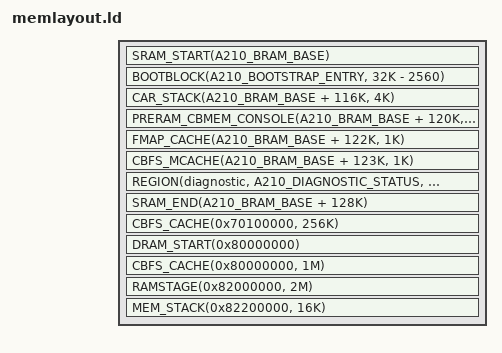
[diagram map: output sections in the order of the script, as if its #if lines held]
/* SPDX-License-Identifier: GPL-2.0-only */
#include <memlayout.h>
#include <arch/header.ld>
#include <soc/addressmap.h>

SECTIONS
{
	SRAM_START(A210_BRAM_BASE)
#if CONFIG(A210_BOOTSTRAP)
	BOOTBLOCK(A210_BOOTSTRAP_ENTRY, 32K - 2560)
#else
	BOOTBLOCK(A210_DDR_ENTRY, 112K)
#endif
	CAR_STACK(A210_BRAM_BASE + 116K, 4K)
	PRERAM_CBMEM_CONSOLE(A210_BRAM_BASE + 120K, 2K)
	FMAP_CACHE(A210_BRAM_BASE + 122K, 1K)
	CBFS_MCACHE(A210_BRAM_BASE + 123K, 1K)
	REGION(diagnostic, A210_DIAGNOSTIC_STATUS, 4K, 4K)
	SRAM_END(A210_BRAM_BASE + 128K)
#if CONFIG(A210_BOOTSTRAP)
	CBFS_CACHE(0x70100000, 256K)
#endif
	DRAM_START(0x80000000)
#if !CONFIG(A210_BOOTSTRAP)
#if ENV_BOOTBLOCK
	/* Temporary read buffer, discarded before OpenSBI is loaded. */
	CBFS_CACHE(0x80000000, 1M)
#else
#if CONFIG(RISCV_OPENSBI)
	OPENSBI(0x80000000, 1M)
#endif
	CBFS_CACHE(0x80100000, 1M)
#endif
#endif
	RAMSTAGE(0x82000000, 2M)
	MEM_STACK(0x82200000, 16K)
}
